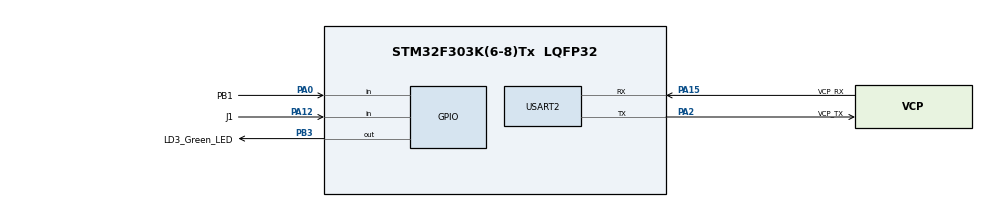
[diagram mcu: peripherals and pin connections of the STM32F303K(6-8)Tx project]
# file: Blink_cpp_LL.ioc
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Mcu.Family=STM32F3
RCC.CortexFreq_Value=8000000
PF0\ /\ OSC_IN.Mode=HSE-External-Clock-Source
PA14.GPIO_Label=SWCLK
PA0.GPIO_Label=PB1
PA12.GPIO_Label=J1
PB3.GPIO_Speed=GPIO_SPEED_FREQ_HIGH
ProjectManager.StackSize=0x400
PA13.Signal=SYS_JTMS-SWDIO
PA15.GPIO_Label=VCP_RX
PA12.Signal=GPIO_Input
ProjectManager.TargetToolchain=STM32CubeIDE
RCC.AHBFreq_Value=8000000
RCC.HSE_VALUE=8000000
board=NUCLEO-F303K8
USART2.VirtualMode-Asynchronous=VM_ASYNC
PA15.Mode=Asynchronous
RCC.APB2Freq_Value=8000000
PF0\ /\ OSC_IN.Signal=RCC_OSC_IN
PA14.Mode=Serial_Wire
PF0\ /\ OSC_IN.GPIO_Label=MCO
PA13.Mode=Serial_Wire
Mcu.Name=STM32F303K(6-8)Tx
PA13.GPIO_Label=SWDIO
PA2.Signal=USART2_TX
PA0.Signal=GPIO_Input
PB3.Signal=GPIO_Output
RCC.SYSCLKFreq_VALUE=8000000
Mcu.Package=LQFP32
PA0.GPIO_PuPd=GPIO_PULLDOWN
PA2.GPIO_Label=VCP_TX
PA14.Signal=SYS_JTCK-SWCLK
PA15.Signal=USART2_RX
ProjectManager.HeapSize=0x200
RCC.HSI_VALUE=8000000
NVIC.PriorityGroup=NVIC_PRIORITYGROUP_4
PA2.Mode=Asynchronous
PA12.GPIO_PuPd=GPIO_PULLUP
RCC.APB1Freq_Value=8000000
PB3.GPIO_Label=LD3_Green_LED

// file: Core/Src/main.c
/* USER CODE BEGIN Header */
/**
  ******************************************************************************
  * @file           : main.c
  * @brief          : Main program body
  ******************************************************************************
  * @attention
  *
  * <h2><center>&copy; Copyright (c) 2021 STMicroelectronics.
  * All rights reserved.</center></h2>
  *
  * This software component is licensed by ST under BSD 3-Clause license,
  * the "License"; You may not use this file except in compliance with the
  * License. You may obtain a copy of the License at:
  *                        opensource.org/licenses/BSD-3-Clause
  *
  ******************************************************************************
  */
/* USER CODE END Header */
#include "main.h"

void SystemClock_Config(void);
static void MX_GPIO_Init(void);
static void MX_USART2_UART_Init(void);

int main(void)
{

  /* MCU Configuration--------------------------------------------------------*/

  /* Reset of all peripherals, Initializes the Flash interface and the Systick. */

  LL_APB2_GRP1_EnableClock(LL_APB2_GRP1_PERIPH_SYSCFG);
  LL_APB1_GRP1_EnableClock(LL_APB1_GRP1_PERIPH_PWR);

  NVIC_SetPriorityGrouping(NVIC_PRIORITYGROUP_4);

  /* System interrupt init*/

  /* Configure the system clock */
  SystemClock_Config();

  /* Initialize all configured peripherals */
  MX_GPIO_Init();
  MX_USART2_UART_Init();

  /* Infinite loop */
  /* USER CODE BEGIN WHILE */
  while (1)
  {
	  uint32_t ticks = HAL_GetTick();
	  bool b = (ticks >> (PB1_get() ? 6 : 8)) & 1;

	  LD3_Green_LED_set(b);

    /* USER CODE END WHILE */

  }
}

void SystemClock_Config(void)
{
  LL_FLASH_SetLatency(LL_FLASH_LATENCY_0);
  while(LL_FLASH_GetLatency()!= LL_FLASH_LATENCY_0)
  {
  }
  LL_RCC_HSI_Enable();

   /* Wait till HSI is ready */
  while(LL_RCC_HSI_IsReady() != 1)
  {

  }
  LL_RCC_HSI_SetCalibTrimming(16);
  LL_RCC_SetAHBPrescaler(LL_RCC_SYSCLK_DIV_1);
  LL_RCC_SetAPB1Prescaler(LL_RCC_APB1_DIV_1);
  LL_RCC_SetAPB2Prescaler(LL_RCC_APB1_DIV_1);
  LL_RCC_SetSysClkSource(LL_RCC_SYS_CLKSOURCE_HSI);

   /* Wait till System clock is ready */
  while(LL_RCC_GetSysClkSource() != LL_RCC_SYS_CLKSOURCE_STATUS_HSI)
  {

  }
  LL_Init1msTick(8000000);
  LL_SetSystemCoreClock(8000000);
}

static void MX_USART2_UART_Init(void)
{

  LL_USART_InitTypeDef USART_InitStruct = {0};

  LL_GPIO_InitTypeDef GPIO_InitStruct = {0};

  /* Peripheral clock enable */
  LL_APB1_GRP1_EnableClock(LL_APB1_GRP1_PERIPH_USART2);

  LL_AHB1_GRP1_EnableClock(LL_AHB1_GRP1_PERIPH_GPIOA);
  /**USART2 GPIO Configuration
  PA2   ------> USART2_TX
  PA15   ------> USART2_RX
  */
  GPIO_InitStruct.Pin = VCP_TX_Pin|VCP_RX_Pin;
  GPIO_InitStruct.Mode = LL_GPIO_MODE_ALTERNATE;
  GPIO_InitStruct.Speed = LL_GPIO_SPEED_FREQ_HIGH;
  GPIO_InitStruct.OutputType = LL_GPIO_OUTPUT_PUSHPULL;
  GPIO_InitStruct.Pull = LL_GPIO_PULL_NO;
  GPIO_InitStruct.Alternate = LL_GPIO_AF_7;
  LL_GPIO_Init(GPIOA, &GPIO_InitStruct);

  USART_InitStruct.BaudRate = 38400;
  USART_InitStruct.DataWidth = LL_USART_DATAWIDTH_8B;
  USART_InitStruct.StopBits = LL_USART_STOPBITS_1;
  USART_InitStruct.Parity = LL_USART_PARITY_NONE;
  USART_InitStruct.TransferDirection = LL_USART_DIRECTION_TX_RX;
  USART_InitStruct.HardwareFlowControl = LL_USART_HWCONTROL_NONE;
  USART_InitStruct.OverSampling = LL_USART_OVERSAMPLING_16;
  LL_USART_Init(USART2, &USART_InitStruct);
  LL_USART_DisableIT_CTS(USART2);
  LL_USART_ConfigAsyncMode(USART2);
  LL_USART_Enable(USART2);

}

static void MX_GPIO_Init(void)
{
  LL_GPIO_InitTypeDef GPIO_InitStruct = {0};

  /* GPIO Ports Clock Enable */
  LL_AHB1_GRP1_EnableClock(LL_AHB1_GRP1_PERIPH_GPIOF);
  LL_AHB1_GRP1_EnableClock(LL_AHB1_GRP1_PERIPH_GPIOA);
  LL_AHB1_GRP1_EnableClock(LL_AHB1_GRP1_PERIPH_GPIOB);

  /**/
  LL_GPIO_ResetOutputPin(LD3_Green_LED_GPIO_Port, LD3_Green_LED_Pin);

  /**/
  GPIO_InitStruct.Pin = PB1_Pin;
  GPIO_InitStruct.Mode = LL_GPIO_MODE_INPUT;
  GPIO_InitStruct.Pull = LL_GPIO_PULL_DOWN;
  LL_GPIO_Init(PB1_GPIO_Port, &GPIO_InitStruct);

  /**/
  GPIO_InitStruct.Pin = J1_Pin;
  GPIO_InitStruct.Mode = LL_GPIO_MODE_INPUT;
  GPIO_InitStruct.Pull = LL_GPIO_PULL_UP;
  LL_GPIO_Init(J1_GPIO_Port, &GPIO_InitStruct);

  /**/
  GPIO_InitStruct.Pin = LD3_Green_LED_Pin;
  GPIO_InitStruct.Mode = LL_GPIO_MODE_OUTPUT;
  GPIO_InitStruct.Speed = LL_GPIO_SPEED_FREQ_HIGH;
  GPIO_InitStruct.OutputType = LL_GPIO_OUTPUT_PUSHPULL;
  GPIO_InitStruct.Pull = LL_GPIO_PULL_NO;
  LL_GPIO_Init(LD3_Green_LED_GPIO_Port, &GPIO_InitStruct);

}

void Error_Handler(void)
{
}

/************************ (C) COPYRIGHT STMicroelectronics *****END OF FILE****/
